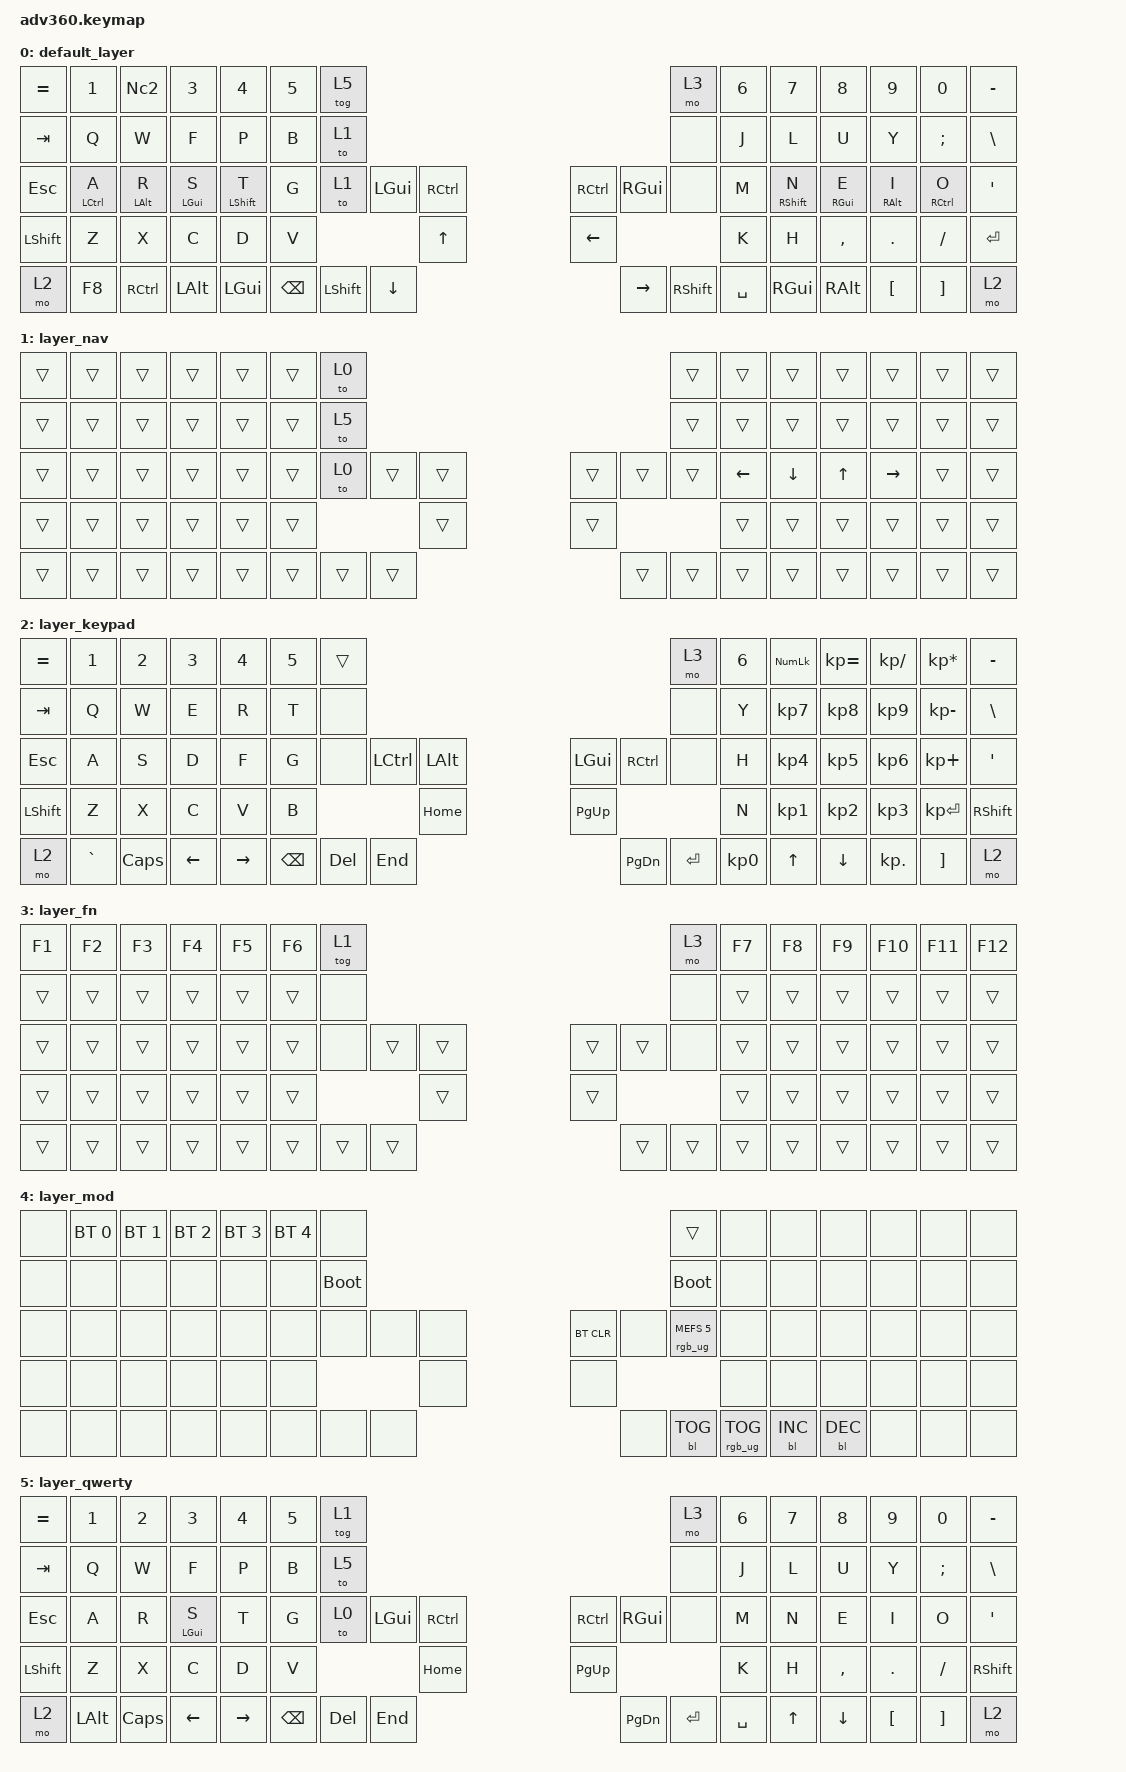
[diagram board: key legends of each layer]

/*
 * Copyright (c) 2020 The ZMK Contributors
 *
 * SPDX-License-Identifier: MIT
 */


/* THIS FILE WAS GENERATED!
 *
 * This file was generated automatically. You may or may not want to
 * edit it directly.
 */

#include <behaviors.dtsi>
#include <dt-bindings/zmk/keys.h>
#include <dt-bindings/zmk/bt.h>
#include <dt-bindings/zmk/rgb.h>
#include <dt-bindings/zmk/backlight.h>

/ {
  behaviors {
    #include "macros.dtsi"
    #include "version.dtsi"

    hm: homerow_mods {
        compatible = "zmk,behavior-hold-tap";
        label = "HOMEROW_MODS";
        #binding-cells = <2>;
        tapping-term-ms = <200>;
        quick_tap_ms = <175>;
        flavor = "tap-preferred";
        bindings = <&kp>, <&kp>;
    };
  };

    keymap {
        compatible = "zmk,keymap";


        default_layer {
            bindings = <
 &kp EQUAL  &kp N1  ç     &kp Nc2          &kp N3         &kp N4            &kp N5              &tog 5                                                                                        &mo 3  &kp N6    &kp N7           &kp N8    &kp N9    &kp N0  &kp MINUS
 &kp TAB    &kp Q        &kp W           &kp F          &kp P             &kp B               &to 1                                                                                        &none   &kp J     &kp L            &kp U     &kp Y  &kp SEMI   &kp BSLH
 &kp ESC    &hm LCTRL A  &hm LEFT_ALT R  &hm LEFT_GUI S &hm LEFT_SHIFT T  &kp G               &to 1   &kp LGUI        &kp RCTRL                        &kp RCTRL         &kp RGUI      &none   &kp M     &hm RIGHT_SHIFT N  &hm RIGHT_GUI E     &hm RIGHT_ALT I     &hm RCTRL O    &kp SQT
 &kp LSHFT  &kp Z        &kp X           &kp C          &kp D    &kp V                                                &kp UP_ARROW                   &kp LEFT_ARROW                               &kp K     &kp H        &kp COMMA   &kp DOT  &kp FSLH  &kp ENTER
 &mo 2      &kp F8       &kp RCTRL       &kp LEFT_ALT   &kp LGUI                            &kp BSPC  &kp LEFT_SHIFT  &kp DOWN_ARROW                  &kp RIGHT_ARROW  &kp RIGHT_SHIFT  &kp SPACE          &kp RGUI    &kp RIGHT_ALT  &kp LBKT  &kp RBKT      &mo 2
          >;
        };

        layer_nav {
            bindings = <
 &trans  &trans  &trans  &trans  &trans  &trans             &to 0                                                  &trans  &trans  &trans  &trans  &trans  &trans  &trans
 &trans  &trans  &trans  &trans  &trans  &trans             &to 5                                                  &trans  &trans  &trans  &trans  &trans  &trans  &trans
          &trans  &trans  &trans  &trans  &trans  &trans             &to 0  &trans  &trans                  &trans  &trans  &trans  &kp LEFT_ARROW  &kp DOWN_ARROW  &kp UP_ARROW  &kp RIGHT_ARROW  &trans  &trans
 &trans  &trans  &trans  &trans  &trans  &trans                            &trans                  &trans                  &trans  &trans  &trans  &trans  &trans  &trans
 &trans  &trans  &trans  &trans  &trans                    &trans  &trans  &trans                  &trans  &trans  &trans          &trans  &trans  &trans  &trans  &trans
            >;
        };

        layer_keypad {
            bindings = <
 &kp EQUAL     &kp N1    &kp N2    &kp N3     &kp N4  &kp N5              &trans                                                                 &mo 3  &kp N6  &kp KP_NUM  &kp KP_EQUAL  &kp KP_DIVIDE  &kp KP_MULTIPLY  &kp MINUS
   &kp TAB      &kp Q     &kp W     &kp E      &kp R   &kp T               &none                                                                 &none   &kp Y   &kp KP_N7     &kp KP_N8      &kp KP_N9     &kp KP_MINUS   &kp BSLH
   &kp ESC      &kp A     &kp S     &kp D      &kp F   &kp G               &none  &kp LCTRL  &kp LALT                   &kp LGUI  &kp RCTRL      &none   &kp H   &kp KP_N4     &kp KP_N5      &kp KP_N6      &kp KP_PLUS    &kp SQT
 &kp LSHFT      &kp Z     &kp X     &kp C      &kp V   &kp B                                 &kp HOME                  &kp PG_UP                         &kp N   &kp KP_N1     &kp KP_N2      &kp KP_N3     &kp KP_ENTER  &kp RSHFT
     &mo 2  &kp GRAVE  &kp CAPS  &kp LEFT  &kp RIGHT                    &kp BSPC    &kp DEL   &kp END                  &kp PG_DN  &kp ENTER  &kp KP_N0              &kp UP      &kp DOWN     &kp KP_DOT         &kp RBKT      &mo 2
            >;
        };

        layer_fn {
            bindings = <
 &kp F1  &kp F2  &kp F3  &kp F4  &kp F5  &kp F6            &tog 1                                                   &mo 3  &kp F7  &kp F8  &kp F9  &kp F10  &kp F11  &kp F12
 &trans  &trans  &trans  &trans  &trans  &trans             &none                                                   &none  &trans  &trans  &trans   &trans   &trans   &trans
 &trans  &trans  &trans  &trans  &trans  &trans             &none  &trans  &trans                  &trans  &trans   &none  &trans  &trans  &trans   &trans   &trans   &trans
 &trans  &trans  &trans  &trans  &trans  &trans                            &trans                  &trans                  &trans  &trans  &trans   &trans   &trans   &trans
 &trans  &trans  &trans  &trans  &trans                    &trans  &trans  &trans                  &trans  &trans  &trans          &trans  &trans   &trans   &trans   &trans
            >;
        };

        layer_mod {
            bindings = <
  &none  &bt BT_SEL 0  &bt BT_SEL 1  &bt BT_SEL 2  &bt BT_SEL 3  &bt BT_SEL 4                  &none                                                                          &trans   &none       &none       &none   &none   &none   &none
  &none         &none         &none         &none         &none         &none            &bootloader                                                                     &bootloader   &none       &none       &none   &none   &none   &none
  &none         &none         &none         &none         &none         &none                  &none   &none   &none                  &bt BT_CLR       &none  &rgb_ug RGB_MEFS_CMD 5   &none       &none       &none   &none   &none   &none
  &none         &none         &none         &none         &none         &none                                  &none                       &none                                       &none       &none       &none   &none   &none   &none
  &none         &none         &none         &none         &none                                &none   &none   &none                       &none  &bl BL_TOG         &rgb_ug RGB_TOG          &bl BL_INC  &bl BL_DEC   &none   &none   &none
            >;
        };


        layer_qwerty {
          bindings = <
              &kp EQUAL    &kp N1    &kp N2          &kp N3     &kp N4  &kp N5              &tog 1                                                                 &mo 3  &kp N6  &kp N7     &kp N8    &kp N9    &kp N0  &kp MINUS
   &kp TAB     &kp Q     &kp W           &kp F      &kp P   &kp B               &to 5                                                                 &none   &kp J   &kp L      &kp U     &kp Y  &kp SEMI   &kp BSLH
   &kp ESC     &kp A     &kp R  &mt LEFT_GUI S      &kp T   &kp G               &to 0  &kp LGUI  &kp RCTRL                  &kp RCTRL   &kp RGUI      &none   &kp M   &kp N      &kp E     &kp I     &kp O    &kp SQT
 &kp LSHFT     &kp Z     &kp X           &kp C      &kp D   &kp V                                 &kp HOME                  &kp PG_UP                         &kp K   &kp H  &kp COMMA   &kp DOT  &kp FSLH  &kp RSHFT
     &mo 2  &kp LALT  &kp CAPS        &kp LEFT  &kp RIGHT                    &kp BSPC   &kp DEL    &kp END                  &kp PG_DN  &kp ENTER  &kp SPACE          &kp UP   &kp DOWN  &kp LBKT  &kp RBKT      &mo 2
            >;
        };

    };
};
